# STM32L15x register map
File version: 1.0
Registers are 32-bit, read-write, reset 0x0 unless marked. A register's access mark holds for its fields unless they carry their own. Offsets are from the block's base; [hi:lo] are bit positions; {n}, {i} and the like mark numbered series; 'fields as' and 'values as' point back to an identical list.

## DMA — DMA controller
Base 0x40026000
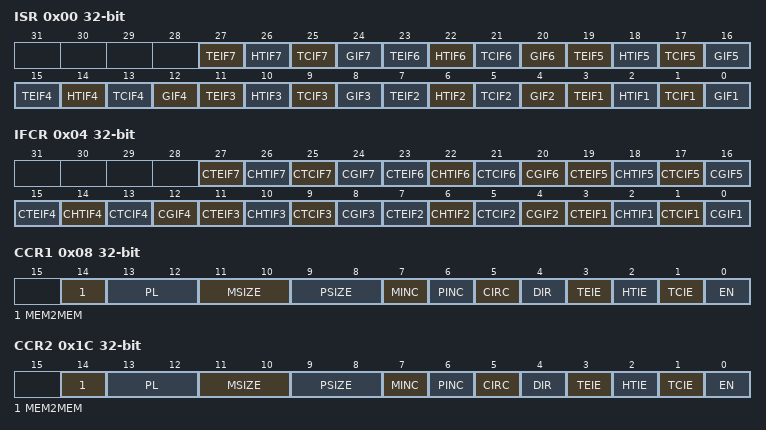
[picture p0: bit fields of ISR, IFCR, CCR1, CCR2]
0x00 ISR ro — DMA interrupt status register
  [4n-1] TEIF{n} (n=1..7), [4n-2] HTIF{n} (n=1..7), [4n-3] TCIF{n} (n=1..7), [4n-4] GIF{n} (n=1..7)
0x04 IFCR wo — DMA interrupt flag clear register
  [4n-1] CTEIF{n} (n=1..7), [4n-2] CHTIF{n} (n=1..7), [4n-3] CTCIF{n} (n=1..7), [4n-4] CGIF{n} (n=1..7)
0x08 CCR1 — DMA channel x configuration register
  [14] MEM2MEM, [13:12] PL, [11:10] MSIZE, [9:8] PSIZE, [7] MINC, [6] PINC, [5] CIRC, [4] DIR, [3] TEIE, [2] HTIE, [1] TCIE, [0] EN
0x0C CNDTR1 ro — DMA channel x number of data register
  [15:0] NDT
0x10 CPAR1 — DMA channel x peripheral address register
  [31:0] PA
{0x0+0x14*i} CMAR{i} (i=1..7) — DMA channel x memory address register
  [31:0] MA
0x1C CCR2 — DMA channel x configuration register
  fields as CCR1
0x20 CNDTR2 — DMA channel x number of data register
  [15:0] NDT
0x24 CPAR2 — DMA channel x peripheral address register
  [31:0] PA
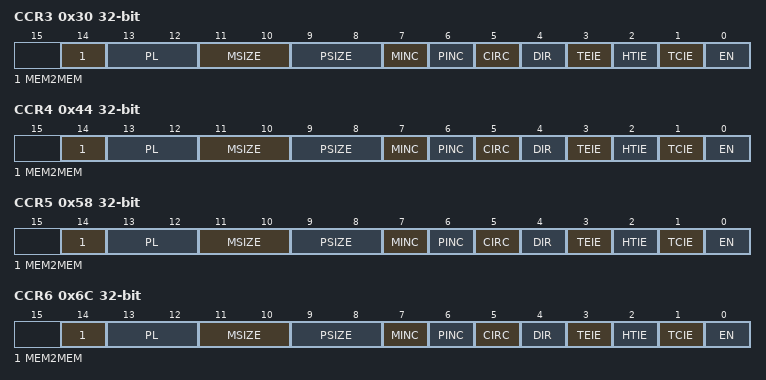
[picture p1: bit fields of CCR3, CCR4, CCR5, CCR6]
0x30 CCR3 — DMA channel x configuration register
  fields as CCR1
0x34 CNDTR3 — DMA channel x number of data register
  [15:0] NDT
0x38 CPAR3 — DMA channel x peripheral address register
  [31:0] PA
0x44 CCR4 — DMA channel x configuration register
  fields as CCR1
0x48 CNDTR4 — DMA channel x number of data register
  [15:0] NDT
0x4C CPAR4 — DMA channel x peripheral address register
  [31:0] PA
0x58 CCR5 — DMA channel x configuration register
  fields as CCR1
0x5C CNDTR5 — DMA channel x number of data register
  [15:0] NDT
0x60 CPAR5 — DMA channel x peripheral address register
  [31:0] PA
0x6C CCR6 — DMA channel x configuration register
  fields as CCR1
0x70 CNDTR6 — DMA channel x number of data register
  [15:0] NDT
0x74 CPAR6 — DMA channel x peripheral address register
  [31:0] PA
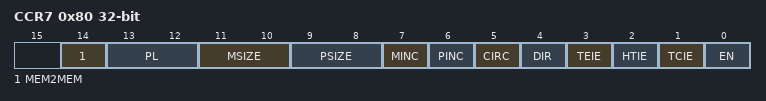
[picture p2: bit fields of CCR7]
0x80 CCR7 — DMA channel x configuration register
  fields as CCR1
0x84 CNDTR7 — DMA channel x number of data register
  [15:0] NDT
0x88 CPAR7 — DMA channel x peripheral address register
  [31:0] PA

## Flash
Base 0x40023C00
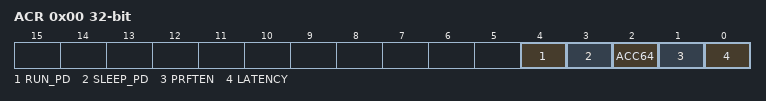
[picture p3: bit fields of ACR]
0x00 ACR access per field — FLASH_ACR
  [4] RUN_PD ro, [3] SLEEP_PD rw, [2] ACC64 rw, [1] PRFTEN ro, [0] LATENCY ro

## RCC — Reset and clock control
Base 0x40023800
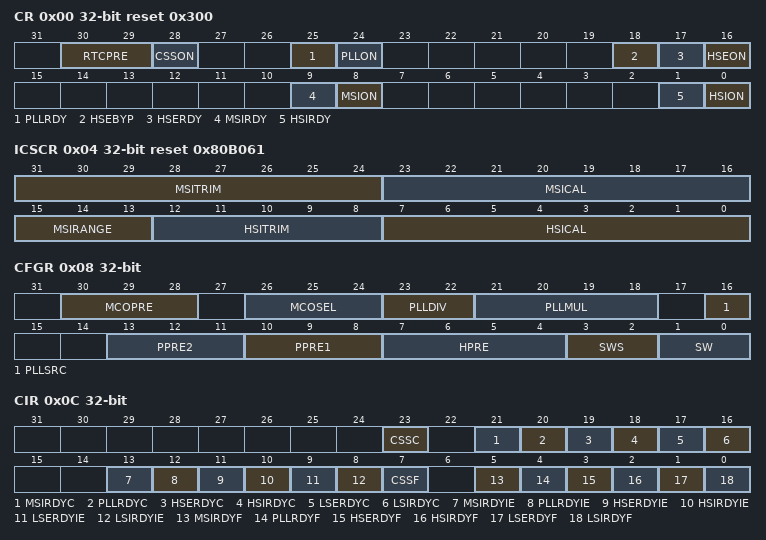
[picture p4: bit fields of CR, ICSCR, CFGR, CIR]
0x00 CR access per field reset 0x300 — Clock control register
  [30:29] RTCPRE rw, [28] CSSON rw, [25] PLLRDY ro, [24] PLLON rw, [18] HSEBYP rw, [17] HSERDY ro, [16] HSEON rw, [9] MSIRDY ro, [8] MSION rw, [1] HSIRDY ro, [0] HSION rw
0x04 ICSCR access per field reset 0x80B061 — Internal clock sources calibration register
  [31:24] MSITRIM rw, [23:16] MSICAL ro, [15:13] MSIRANGE rw, [12:8] HSITRIM rw, [7:0] HSICAL ro
0x08 CFGR access per field — Clock configuration register
  [30:28] MCOPRE rw, [26:24] MCOSEL rw, [23:22] PLLDIV rw, [21:18] PLLMUL rw, [16] PLLSRC rw, [13:11] PPRE2 rw, [10:8] PPRE1 rw, [7:4] HPRE rw, [3:2] SWS ro, [1:0] SW rw
0x0C CIR access per field — Clock interrupt register
  [23] CSSC wo, [21] MSIRDYC wo, [20] PLLRDYC wo, [19] HSERDYC wo, [18] HSIRDYC wo, [17] LSERDYC wo, [16] LSIRDYC wo, [13] MSIRDYIE rw, [12] PLLRDYIE rw, [11] HSERDYIE rw, [10] HSIRDYIE rw, [9] LSERDYIE rw, [8] LSIRDYIE rw, [7] CSSF ro, [5] MSIRDYF ro, [4] PLLRDYF ro, [3] HSERDYF ro, [2] HSIRDYF ro, [1] LSERDYF ro, [0] LSIRDYF ro
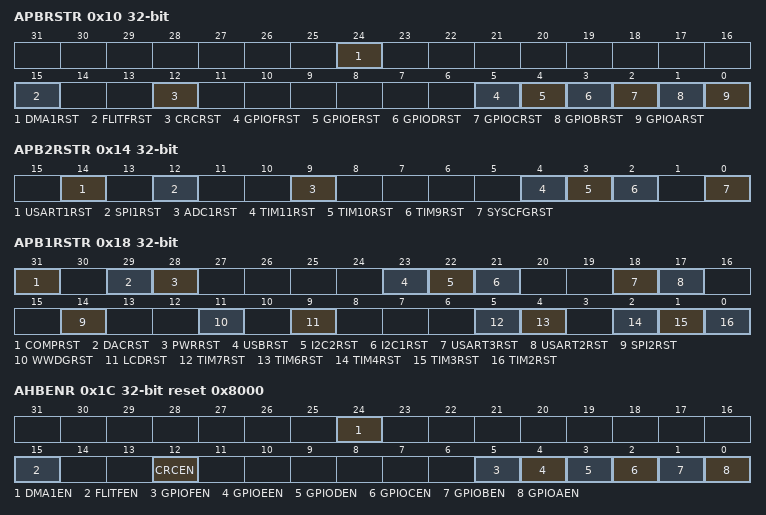
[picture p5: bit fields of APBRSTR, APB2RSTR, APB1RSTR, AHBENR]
0x10 APBRSTR — AHB peripheral reset register
  [24] DMA1RST, [15] FLITFRST, [12] CRCRST, [5] GPIOFRST, [4] GPIOERST, [3] GPIODRST, [2] GPIOCRST, [1] GPIOBRST, [0] GPIOARST
0x14 APB2RSTR — APB2 peripheral reset register
  [14] USART1RST, [12] SPI1RST, [9] ADC1RST, [4] TIM11RST, [3] TIM10RST, [2] TIM9RST, [0] SYSCFGRST
0x18 APB1RSTR — APB1 peripheral reset register
  [31] COMPRST, [29] DACRST, [28] PWRRST, [23] USBRST, [22] I2C2RST, [21] I2C1RST, [18] USART3RST, [17] USART2RST, [14] SPI2RST, [11] WWDGRST, [9] LCDRST, [5] TIM7RST, [4] TIM6RST, [2] TIM4RST, [1] TIM3RST, [0] TIM2RST
0x1C AHBENR reset 0x8000 — AHB peripheral clock enable register
  [24] DMA1EN, [15] FLITFEN, [12] CRCEN, [5] GPIOFEN, [4] GPIOEEN, [3] GPIODEN, [2] GPIOCEN, [1] GPIOBEN, [0] GPIOAEN
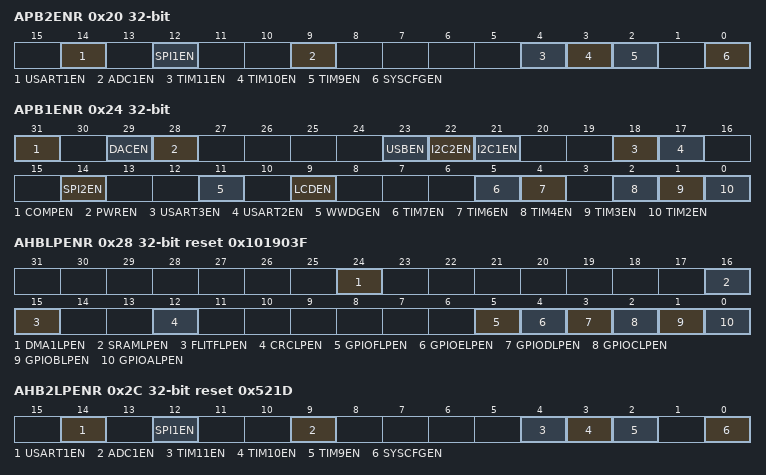
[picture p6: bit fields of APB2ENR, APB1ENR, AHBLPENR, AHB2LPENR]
0x20 APB2ENR — APB2 peripheral clock enable register
  [14] USART1EN, [12] SPI1EN, [9] ADC1EN, [4] TIM11EN, [3] TIM10EN, [2] TIM9EN, [0] SYSCFGEN
0x24 APB1ENR — APB1 peripheral clock enable register
  [31] COMPEN, [29] DACEN, [28] PWREN, [23] USBEN, [22] I2C2EN, [21] I2C1EN, [18] USART3EN, [17] USART2EN, [14] SPI2EN, [11] WWDGEN, [9] LCDEN, [5] TIM7EN, [4] TIM6EN, [2] TIM4EN, [1] TIM3EN, [0] TIM2EN
0x28 AHBLPENR reset 0x101903F — AHB peripheral clock enable in low power mode register
  [24] DMA1LPEN, [16] SRAMLPEN, [15] FLITFLPEN, [12] CRCLPEN, [5] GPIOFLPEN, [4] GPIOELPEN, [3] GPIODLPEN, [2] GPIOCLPEN, [1] GPIOBLPEN, [0] GPIOALPEN
0x2C AHB2LPENR reset 0x521D — APB2 peripheral clock enable in low power mode register
  fields as APB2ENR
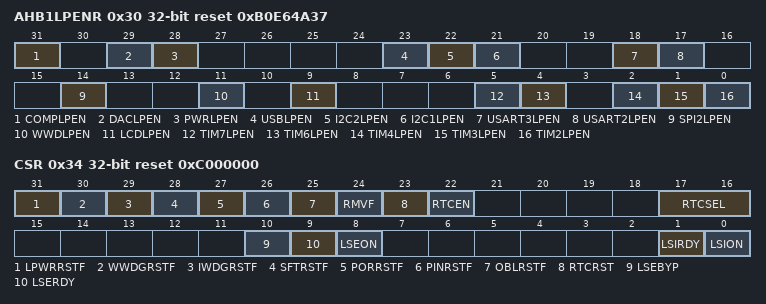
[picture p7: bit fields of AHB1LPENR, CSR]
0x30 AHB1LPENR reset 0xB0E64A37 — APB1 peripheral clock enable in low power mode register
  [31] COMPLPEN, [29] DACLPEN, [28] PWRLPEN, [23] USBLPEN, [22] I2C2LPEN, [21] I2C1LPEN, [18] USART3LPEN, [17] USART2LPEN, [14] SPI2LPEN, [11] WWDLPEN, [9] LCDLPEN, [5] TIM7LPEN, [4] TIM6LPEN, [2] TIM4LPEN, [1] TIM3LPEN, [0] TIM2LPEN
0x34 CSR reset 0xC000000 — Control/status register
  [31] LPWRRSTF, [30] WWDGRSTF, [29] IWDGRSTF, [28] SFTRSTF, [27] PORRSTF, [26] PINRSTF, [25] OBLRSTF, [24] RMVF, [23] RTCRST, [22] RTCEN, [17:16] RTCSEL, [10] LSEBYP, [9] LSERDY, [8] LSEON, [1] LSIRDY, [0] LSION
